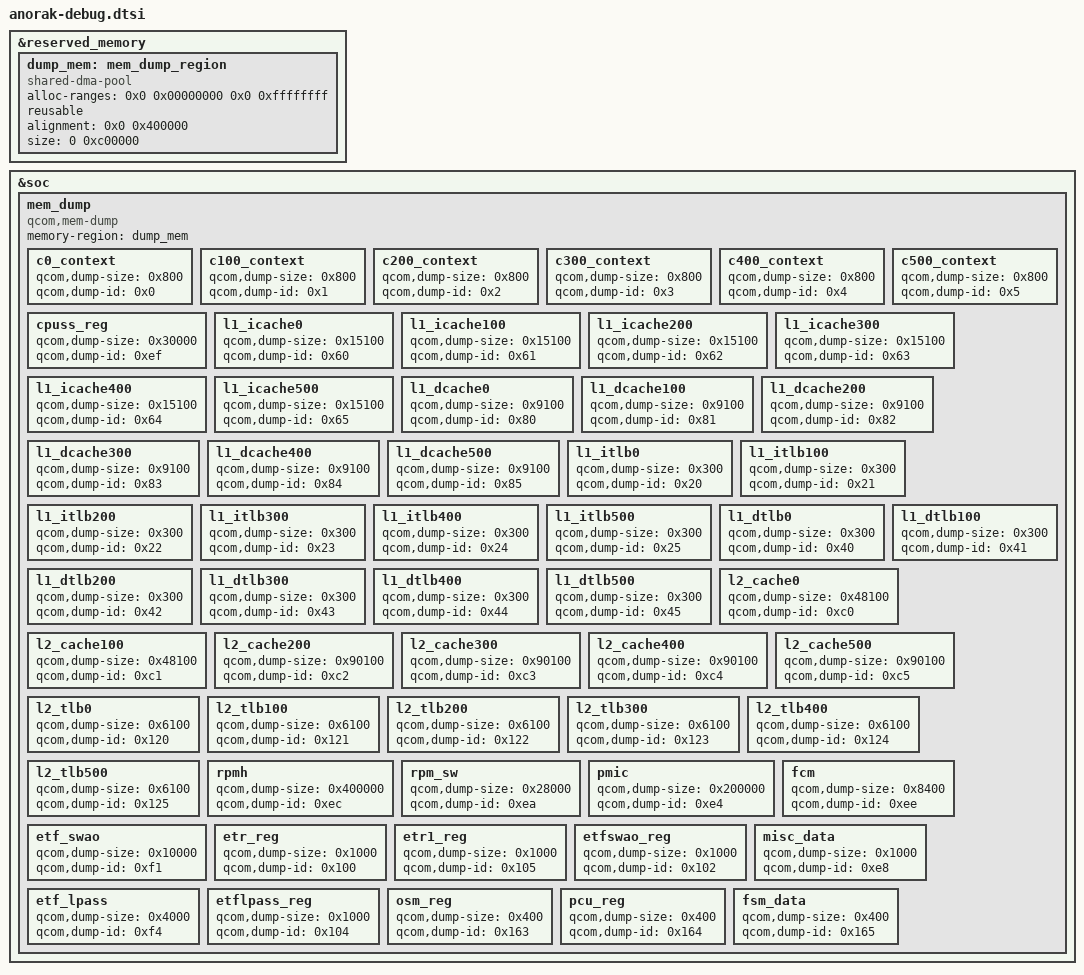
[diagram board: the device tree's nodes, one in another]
#include <dt-bindings/soc/qcom,dcc_v2.h>

&reserved_memory {
	#address-cells = <2>;
	#size-cells = <2>;
	ranges;

	dump_mem: mem_dump_region {
		compatible = "shared-dma-pool";
		alloc-ranges = <0x0 0x00000000 0x0 0xffffffff>;
		reusable;
		alignment = <0x0 0x400000>;
		size = <0 0xc00000>;
	};
};

&soc {
	mem_dump {
		compatible = "qcom,mem-dump";
		memory-region = <&dump_mem>;

		c0_context {
			qcom,dump-size = <0x800>;
			qcom,dump-id = <0x0>;
		};

		c100_context {
			qcom,dump-size = <0x800>;
			qcom,dump-id = <0x1>;
		};

		c200_context {
			qcom,dump-size = <0x800>;
			qcom,dump-id = <0x2>;
		};

		c300_context {
			qcom,dump-size = <0x800>;
			qcom,dump-id = <0x3>;
		};

		c400_context {
			qcom,dump-size = <0x800>;
			qcom,dump-id = <0x4>;
		};

		c500_context {
			qcom,dump-size = <0x800>;
			qcom,dump-id = <0x5>;
		};

		cpuss_reg {
			qcom,dump-size = <0x30000>;
			qcom,dump-id = <0xef>;
		};

		l1_icache0 {
			qcom,dump-size = <0x15100>;
			qcom,dump-id = <0x60>;
		};

		l1_icache100 {
			qcom,dump-size = <0x15100>;
			qcom,dump-id = <0x61>;
		};

		l1_icache200 {
			qcom,dump-size = <0x15100>;
			qcom,dump-id = <0x62>;
		};

		l1_icache300 {
			qcom,dump-size = <0x15100>;
			qcom,dump-id = <0x63>;
		};

		l1_icache400 {
			qcom,dump-size = <0x15100>;
			qcom,dump-id = <0x64>;
		};

		l1_icache500 {
			qcom,dump-size = <0x15100>;
			qcom,dump-id = <0x65>;
		};

		l1_dcache0 {
			qcom,dump-size = <0x9100>;
			qcom,dump-id = <0x80>;
		};

		l1_dcache100 {
			qcom,dump-size = <0x9100>;
			qcom,dump-id = <0x81>;
		};

		l1_dcache200 {
			qcom,dump-size = <0x9100>;
			qcom,dump-id = <0x82>;
		};

		l1_dcache300 {
			qcom,dump-size = <0x9100>;
			qcom,dump-id = <0x83>;
		};

		l1_dcache400 {
			qcom,dump-size = <0x9100>;
			qcom,dump-id = <0x84>;
		};

		l1_dcache500 {
			qcom,dump-size = <0x9100>;
			qcom,dump-id = <0x85>;
		};

		l1_itlb0 {
			qcom,dump-size = <0x300>;
			qcom,dump-id = <0x20>;
		};

		l1_itlb100 {
			qcom,dump-size = <0x300>;
			qcom,dump-id = <0x21>;
		};

		l1_itlb200 {
			qcom,dump-size = <0x300>;
			qcom,dump-id = <0x22>;
		};

		l1_itlb300 {
			qcom,dump-size = <0x300>;
			qcom,dump-id = <0x23>;
		};

		l1_itlb400 {
			qcom,dump-size = <0x300>;
			qcom,dump-id = <0x24>;
		};

		l1_itlb500 {
			qcom,dump-size = <0x300>;
			qcom,dump-id = <0x25>;
		};

		l1_dtlb0 {
			qcom,dump-size = <0x300>;
			qcom,dump-id = <0x40>;
		};

		l1_dtlb100 {
			qcom,dump-size = <0x300>;
			qcom,dump-id = <0x41>;
		};

		l1_dtlb200 {
			qcom,dump-size = <0x300>;
			qcom,dump-id = <0x42>;
		};

		l1_dtlb300 {
			qcom,dump-size = <0x300>;
			qcom,dump-id = <0x43>;
		};


		l1_dtlb400 {
			qcom,dump-size = <0x300>;
			qcom,dump-id = <0x44>;
		};

		l1_dtlb500 {
			qcom,dump-size = <0x300>;
			qcom,dump-id = <0x45>;
		};

		l2_cache0 {
			qcom,dump-size = <0x48100>;
			qcom,dump-id = <0xc0>;
		};

		l2_cache100 {
			qcom,dump-size = <0x48100>;
			qcom,dump-id = <0xc1>;
		};

		l2_cache200 {
			qcom,dump-size = <0x90100>;
			qcom,dump-id = <0xc2>;
		};

		l2_cache300 {
			qcom,dump-size = <0x90100>;
			qcom,dump-id = <0xc3>;
		};

		l2_cache400 {
			qcom,dump-size = <0x90100>;
			qcom,dump-id = <0xc4>;
		};

		l2_cache500 {
			qcom,dump-size = <0x90100>;
			qcom,dump-id = <0xc5>;
		};

		l2_tlb0 {
			qcom,dump-size = <0x6100>;
			qcom,dump-id = <0x120>;
		};

		l2_tlb100 {
			qcom,dump-size = <0x6100>;
			qcom,dump-id = <0x121>;
		};

		l2_tlb200 {
			qcom,dump-size = <0x6100>;
			qcom,dump-id = <0x122>;
		};

		l2_tlb300 {
			qcom,dump-size = <0x6100>;
			qcom,dump-id = <0x123>;
		};

		l2_tlb400 {
			qcom,dump-size = <0x6100>;
			qcom,dump-id = <0x124>;
		};

		l2_tlb500 {
			qcom,dump-size = <0x6100>;
			qcom,dump-id = <0x125>;
		};

		rpmh {
			qcom,dump-size = <0x400000>;
			qcom,dump-id = <0xec>;
		};

		rpm_sw {
			qcom,dump-size = <0x28000>;
			qcom,dump-id = <0xea>;
		};

		pmic {
			qcom,dump-size = <0x200000>;
			qcom,dump-id = <0xe4>;
		};

		fcm {
			qcom,dump-size = <0x8400>;
			qcom,dump-id = <0xee>;
		};

		etf_swao {
			qcom,dump-size = <0x10000>;
			qcom,dump-id = <0xf1>;
		};

		etr_reg {
			qcom,dump-size = <0x1000>;
			qcom,dump-id = <0x100>;
		};

		etr1_reg {
			qcom,dump-size = <0x1000>;
			qcom,dump-id = <0x105>;
		};

		etfswao_reg {
			qcom,dump-size = <0x1000>;
			qcom,dump-id = <0x102>;
		};

		misc_data {
			qcom,dump-size = <0x1000>;
			qcom,dump-id = <0xe8>;
		};

		etf_lpass {
			qcom,dump-size = <0x4000>;
			qcom,dump-id = <0xf4>;
		};

		etflpass_reg {
			qcom,dump-size = <0x1000>;
			qcom,dump-id = <0x104>;
		};

		osm_reg {
			qcom,dump-size = <0x400>;
			qcom,dump-id = <0x163>;
		};

		pcu_reg {
			qcom,dump-size = <0x400>;
			qcom,dump-id = <0x164>;
		};

		fsm_data {
			qcom,dump-size = <0x400>;
			qcom,dump-id = <0x165>;
		};
	};
};
